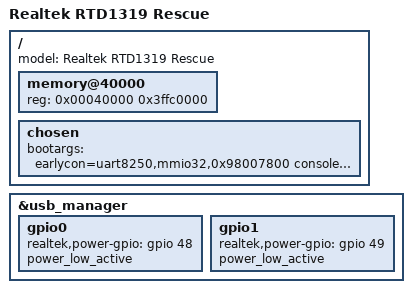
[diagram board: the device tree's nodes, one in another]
// SPDX-License-Identifier: (GPL-2.0-or-later OR BSD-2-Clause)
/*
 * Copyright (c) 2019 Realtek Semiconductor Corp.
 */

/dts-v1/;

#include "rtd13xx-rescue.dtsi"

/ {
	model = "Realtek RTD1319 Rescue";

	memory@40000 {
		device_type = "memory";
		reg = <0x00040000 0x3ffc0000>; /* 1 GiB */
	};

	chosen {
		bootargs = "earlycon=uart8250,mmio32,0x98007800 console=ttyS0,460800 init=/init androidboot.storage=emmc androidboot.hardware=hank NO_RESERVE";
	};
};

&usb_manager {
	status = "okay";

	gpio0 {
		realtek,power-gpio = <&gpio 48 GPIO_ACTIVE_HIGH>;
		power_low_active;
	};

	gpio1 {
		realtek,power-gpio = <&gpio 49 GPIO_ACTIVE_HIGH>;
		power_low_active;
	};
};
